AUTOSAR XML (schema 314)
package /ComponentType
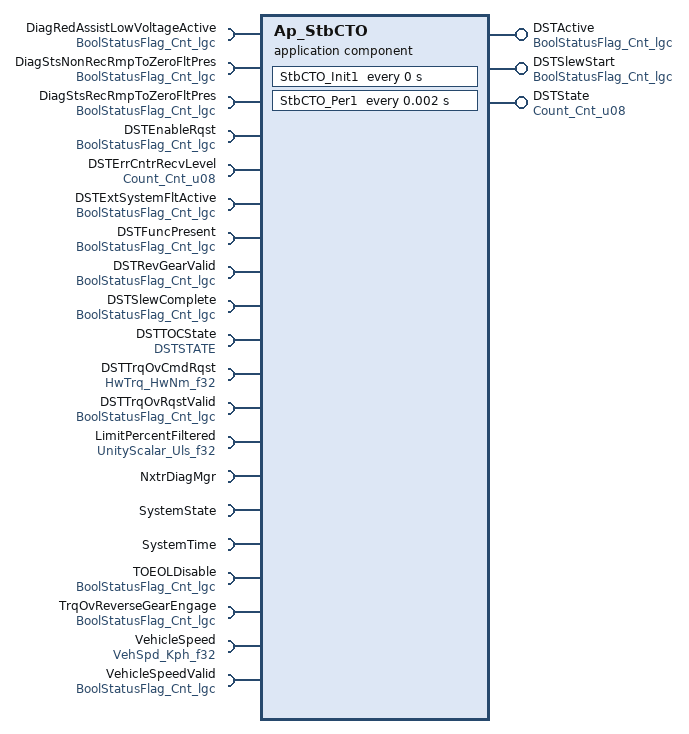
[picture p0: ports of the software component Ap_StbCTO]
  application software component type Ap_StbCTO
    provide port DSTActive: unqueued-sender-com-spec{data-element=Cnt_lgc, can-invalidate=false, init-value=D_FALSE_CNT_LGC}, provided-interface=BoolStatusFlag_Cnt_lgc
    provide port DSTSlewStart: unqueued-sender-com-spec{data-element=Cnt_lgc, can-invalidate=false, init-value=D_FALSE_CNT_LGC}, provided-interface=BoolStatusFlag_Cnt_lgc
    provide port DSTState: unqueued-sender-com-spec{data-element=Cnt_u08, can-invalidate=false, init-value=D_ZERO_CNT_U8}, provided-interface=Count_Cnt_u08
    20 x require port:
      DiagRedAssistLowVoltageActive: unqueued-receiver-com-spec{data-element=Cnt_lgc, init-value=D_FALSE_CNT_LGC}, required-interface=BoolStatusFlag_Cnt_lgc
      DiagStsNonRecRmpToZeroFltPres: unqueued-receiver-com-spec{data-element=Cnt_lgc, init-value=D_FALSE_CNT_LGC}, required-interface=BoolStatusFlag_Cnt_lgc
      DiagStsRecRmpToZeroFltPres: unqueued-receiver-com-spec{data-element=Cnt_lgc, init-value=D_FALSE_CNT_LGC}, required-interface=BoolStatusFlag_Cnt_lgc
      DSTEnableRqst: unqueued-receiver-com-spec{data-element=Cnt_lgc, init-value=D_FALSE_CNT_LGC}, required-interface=BoolStatusFlag_Cnt_lgc
      DSTErrCntrRecvLevel: unqueued-receiver-com-spec{data-element=Cnt_u08, init-value=D_ZERO_CNT_U8}, required-interface=Count_Cnt_u08
      DSTExtSystemFltActive: unqueued-receiver-com-spec{data-element=Cnt_lgc, init-value=D_FALSE_CNT_LGC}, required-interface=BoolStatusFlag_Cnt_lgc
      DSTFuncPresent: unqueued-receiver-com-spec{data-element=Cnt_lgc, init-value=D_FALSE_CNT_LGC}, required-interface=BoolStatusFlag_Cnt_lgc
      DSTRevGearValid: unqueued-receiver-com-spec{data-element=Cnt_lgc, init-value=D_FALSE_CNT_LGC}, required-interface=BoolStatusFlag_Cnt_lgc
      DSTSlewComplete: unqueued-receiver-com-spec{data-element=Cnt_lgc, init-value=D_FALSE_CNT_LGC}, required-interface=BoolStatusFlag_Cnt_lgc
      DSTTOCState: unqueued-receiver-com-spec{data-element=Uls_enum, init-value=D_DSTINITVAL_U8}, required-interface=DSTSTATE
      DSTTrqOvCmdRqst: unqueued-receiver-com-spec{data-element=HwNm_f32, init-value=D_ZERO_ULS_F32}, required-interface=HwTrq_HwNm_f32
      DSTTrqOvRqstValid: unqueued-receiver-com-spec{data-element=Cnt_lgc, init-value=D_FALSE_CNT_LGC}, required-interface=BoolStatusFlag_Cnt_lgc
      LimitPercentFiltered: unqueued-receiver-com-spec{data-element=Uls_f32, init-value=D_ZERO_ULS_F32}, required-interface=UnityScalar_Uls_f32
      NxtrDiagMgr: required-com-specs=[GetNTCActive, GetNTCFailed, GetNTCStatus, SetNTCStatus], required-interface=NxtrDiagMgr
      SystemState: required-interface=SystemState
      SystemTime: required-interface=SystemTime
        required-com-specs:
          DtrmnElapsedTime_mS_u16
          DtrmnElapsedTime_mS_u32
          DtrmnElapsedTime_uS_u16
          DtrmnElapsedTime_uS_u32
          GetSystemTime_mS_u32
          GetSystemTime_uS_u32
      TOEOLDisable: unqueued-receiver-com-spec{data-element=Cnt_lgc, init-value=D_FALSE_CNT_LGC}, required-interface=BoolStatusFlag_Cnt_lgc
      TrqOvReverseGearEngage: unqueued-receiver-com-spec{data-element=Cnt_lgc, init-value=D_FALSE_CNT_LGC}, required-interface=BoolStatusFlag_Cnt_lgc
      VehicleSpeed: unqueued-receiver-com-spec{data-element=Kph_f32, init-value=D_ZERO_ULS_F32}, required-interface=VehSpd_Kph_f32
      VehicleSpeedValid: unqueued-receiver-com-spec{data-element=Cnt_lgc, init-value=D_FALSE_CNT_LGC}, required-interface=BoolStatusFlag_Cnt_lgc
  internal behavior Ap_StbCTO_InternalBehavior: component=Ap_StbCTO
    timing event StbCTO_Init1_InitEvent: start-on-event=StbCTO_Init1, period=0
    timing event TMT_StbCTO_Per1: mode-dependency=dependent-on-mode=SystemState.Mode.OFF, start-on-event=StbCTO_Per1, period=0.002
    port-api-options:
      enable-take-address=false, indirect-api=false, port=DiagRedAssistLowVoltageActive
      enable-take-address=false, indirect-api=false, port=DiagStsNonRecRmpToZeroFltPres
      enable-take-address=false, indirect-api=false, port=DiagStsRecRmpToZeroFltPres
      enable-take-address=false, indirect-api=false, port=DSTActive
      enable-take-address=false, indirect-api=false, port=DSTEnableRqst
      enable-take-address=false, indirect-api=false, port=DSTErrCntrRecvLevel
      enable-take-address=false, indirect-api=false, port=DSTExtSystemFltActive
      enable-take-address=false, indirect-api=false, port=DSTFuncPresent
      enable-take-address=false, indirect-api=false, port=DSTRevGearValid
      enable-take-address=false, indirect-api=false, port=DSTSlewComplete
      enable-take-address=false, indirect-api=false, port=DSTSlewStart
      enable-take-address=false, indirect-api=false, port=DSTState
      enable-take-address=false, indirect-api=false, port=DSTTOCState
      enable-take-address=false, indirect-api=false, port=DSTTrqOvCmdRqst
      enable-take-address=false, indirect-api=false, port=DSTTrqOvRqstValid
      enable-take-address=false, indirect-api=false, port=LimitPercentFiltered
      enable-take-address=false, indirect-api=false, port=NxtrDiagMgr
      enable-take-address=false, indirect-api=false, port=SystemState
      enable-take-address=false, indirect-api=false, port=SystemTime
      enable-take-address=false, indirect-api=false, port=TOEOLDisable
      enable-take-address=false, indirect-api=false, port=TrqOvReverseGearEngage
      enable-take-address=false, indirect-api=false, port=VehicleSpeed
      enable-take-address=false, indirect-api=false, port=VehicleSpeedValid
    runnable StbCTO_Init1
      data write access WRITE_DSTActive_Cnt_lgc: data-element=DSTActive.Cnt_lgc
      data write access WRITE_DSTSlewStart_Cnt_lgc: data-element=DSTSlewStart.Cnt_lgc
      sync call SC_SystemTime_GetSystemTime_mS_u32: operation=SystemTime.GetSystemTime_mS_u32, timeout=0
    runnable StbCTO_Per1
      17 x data read access:
        READ_DiagRedAssistLowVoltageActive_Cnt_lgc: data-element=DiagRedAssistLowVoltageActive.Cnt_lgc
        READ_DiagStsNonRecRmpToZeroFltPres_Cnt_lgc: data-element=DiagStsNonRecRmpToZeroFltPres.Cnt_lgc
        READ_DiagStsRecRmpToZeroFltPres_Cnt_lgc: data-element=DiagStsRecRmpToZeroFltPres.Cnt_lgc
        READ_DSTEnableRqst_Cnt_lgc: data-element=DSTEnableRqst.Cnt_lgc
        READ_DSTErrCntrRecvLevel_Cnt_u08: data-element=DSTErrCntrRecvLevel.Cnt_u08
        READ_DSTExtSystemFltActive_Cnt_lgc: data-element=DSTExtSystemFltActive.Cnt_lgc
        READ_DSTFuncPresent_Cnt_lgc: data-element=DSTFuncPresent.Cnt_lgc
        READ_DSTRevGearValid_Cnt_lgc: data-element=DSTRevGearValid.Cnt_lgc
        READ_DSTSlewComplete_Cnt_lgc: data-element=DSTSlewComplete.Cnt_lgc
        READ_DSTTOCState_Uls_enum: data-element=DSTTOCState.Uls_enum
        READ_DSTTrqOvCmdRqst_HwNm_f32: data-element=DSTTrqOvCmdRqst.HwNm_f32
        READ_DSTTrqOvRqstValid_Cnt_lgc: data-element=DSTTrqOvRqstValid.Cnt_lgc
        READ_LimitPercentFiltered_Uls_f32: data-element=LimitPercentFiltered.Uls_f32
        READ_TOEOLDisable_Cnt_lgc: data-element=TOEOLDisable.Cnt_lgc
        READ_TrqOvReverseGearEngage_Cnt_lgc: data-element=TrqOvReverseGearEngage.Cnt_lgc
        READ_VehicleSpeed_Kph_f32: data-element=VehicleSpeed.Kph_f32
        READ_VehicleSpeedValid_Cnt_lgc: data-element=VehicleSpeedValid.Cnt_lgc
      data write access WRITE_DSTActive_Cnt_lgc: data-element=DSTActive.Cnt_lgc
      data write access WRITE_DSTSlewStart_Cnt_lgc: data-element=DSTSlewStart.Cnt_lgc
      data write access WRITE_DSTState_Cnt_u08: data-element=DSTState.Cnt_u08
      5 x sync call, all with timeout=0:
        SC_NxtrDiagMgr_GetNTCActive: operation=NxtrDiagMgr.GetNTCActive
        SC_NxtrDiagMgr_GetNTCFailed: operation=NxtrDiagMgr.GetNTCFailed
        SC_NxtrDiagMgr_SetNTCStatus: operation=NxtrDiagMgr.SetNTCStatus
        SC_SystemTime_DtrmnElapsedTime_mS_u16: operation=SystemTime.DtrmnElapsedTime_mS_u16
        SC_SystemTime_GetSystemTime_mS_u32: operation=SystemTime.GetSystemTime_mS_u32
  swc implementation Ap_StbCTO_Implementation: behavior=Ap_StbCTO_InternalBehavior
    code-descriptors:
      code Code: type=SRC
